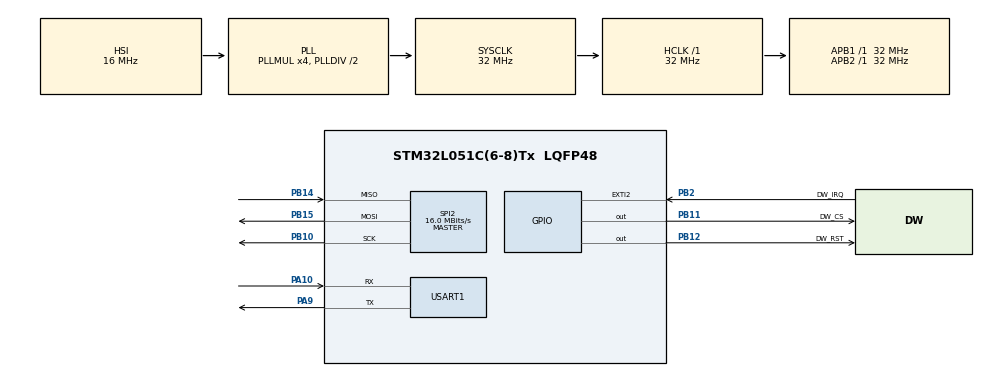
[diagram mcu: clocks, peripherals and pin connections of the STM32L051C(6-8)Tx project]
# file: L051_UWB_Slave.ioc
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Mcu.Family=STM32L0
Mcu.Name=STM32L051C(6-8)Tx
Mcu.Package=LQFP48
NVIC.EXTI2_3_IRQn=true\:0\:0\:false\:false\:true\:true\:true
PA10.Mode=Asynchronous
PA10.Signal=USART1_RX
PA9.Mode=Asynchronous
PA9.Signal=USART1_TX
PB10.Mode=Full_Duplex_Master
PB10.Signal=SPI2_SCK
PB11.GPIO_Label=DW_CS
PB11.GPIO_Speed=GPIO_SPEED_FREQ_VERY_HIGH
PB11.PinState=GPIO_PIN_SET
PB11.Signal=GPIO_Output
PB12.GPIO_Label=DW_RST
PB12.GPIO_Speed=GPIO_SPEED_FREQ_VERY_HIGH
PB12.PinState=GPIO_PIN_SET
PB12.Signal=GPIO_Output
PB14.Mode=Full_Duplex_Master
PB14.Signal=SPI2_MISO
PB15.Mode=Full_Duplex_Master
PB15.Signal=SPI2_MOSI
PB2.GPIO_Label=DW_IRQ
PB2.Signal=GPXTI2
PH0-OSC_IN.Mode=HSE-External-Oscillator
PH0-OSC_IN.Signal=RCC_OSC_IN
PH1-OSC_OUT.Mode=HSE-External-Oscillator
PH1-OSC_OUT.Signal=RCC_OSC_OUT
ProjectManager.HeapSize=0x200
ProjectManager.StackSize=0x400
ProjectManager.TargetToolchain=EWARM V8.32
RCC.AHBFreq_Value=32000000
RCC.APB1Freq_Value=32000000
RCC.APB1TimFreq_Value=32000000
RCC.APB2Freq_Value=32000000
RCC.APB2TimFreq_Value=32000000
RCC.HCLKFreq_Value=32000000
RCC.HSE_VALUE=8000000
RCC.HSI16_VALUE=16000000
RCC.HSI_VALUE=16000000
RCC.LSE_VALUE=32768
RCC.MSI_VALUE=2097000
RCC.PLLMUL=RCC_PLLMUL_4
RCC.SYSCLKFreq_VALUE=32000000
RCC.SYSCLKSource=RCC_SYSCLKSOURCE_PLLCLK
RCC.VCOOutputFreq_Value=64000000
SPI2.CalculateBaudRate=16.0 MBits/s
SPI2.Direction=SPI_DIRECTION_2LINES
SPI2.Mode=SPI_MODE_MASTER
SPI2.VirtualType=VM_MASTER
USART1.VirtualMode-Asynchronous=VM_ASYNC
board=custom

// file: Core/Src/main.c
/* USER CODE BEGIN Header */
/**
  ******************************************************************************
  * @file           : main.c
  * @brief          : Main program body
  ******************************************************************************
  * @attention
  *
  * <h2><center>&copy; Copyright (c) 2021 STMicroelectronics.
  * All rights reserved.</center></h2>
  *
  * This software component is licensed by ST under BSD 3-Clause license,
  * the "License"; You may not use this file except in compliance with the
  * License. You may obtain a copy of the License at:
  *                        opensource.org/licenses/BSD-3-Clause
  *
  ******************************************************************************
  */
/* USER CODE END Header */
#include "main.h"
#include "spi.h"
#include "usart.h"
#include "gpio.h"

/* USER CODE BEGIN Includes */
#include "port.h"

// DW1000
#include "deca_device_api.h"
#include "deca_regs.h"

/* USER CODE END Includes */

void SystemClock_Config(void);

int main(void)
{

  /* MCU Configuration--------------------------------------------------------*/

  /* Reset of all peripherals, Initializes the Flash interface and the Systick. */
  HAL_Init();

  /* Configure the system clock */
  SystemClock_Config();

  /* Initialize all configured peripherals */
  MX_GPIO_Init();
  MX_SPI2_Init();
  MX_USART1_UART_Init();
  /* USER CODE BEGIN 2 */
  setup_DW1000RSTnIRQ(0);

  /* USER CODE END 2 */

  /* Infinite loop */
  while (1)
  {

  }
}

void SystemClock_Config(void)
{
  RCC_OscInitTypeDef RCC_OscInitStruct = {0};
  RCC_ClkInitTypeDef RCC_ClkInitStruct = {0};
  RCC_PeriphCLKInitTypeDef PeriphClkInit = {0};

  /** Configure the main internal regulator output voltage
  */
  __HAL_PWR_VOLTAGESCALING_CONFIG(PWR_REGULATOR_VOLTAGE_SCALE1);
  /** Initializes the RCC Oscillators according to the specified parameters
  * in the RCC_OscInitTypeDef structure.
  */
  RCC_OscInitStruct.OscillatorType = RCC_OSCILLATORTYPE_HSI;
  RCC_OscInitStruct.HSIState = RCC_HSI_ON;
  RCC_OscInitStruct.HSICalibrationValue = RCC_HSICALIBRATION_DEFAULT;
  RCC_OscInitStruct.PLL.PLLState = RCC_PLL_ON;
  RCC_OscInitStruct.PLL.PLLSource = RCC_PLLSOURCE_HSI;
  RCC_OscInitStruct.PLL.PLLMUL = RCC_PLLMUL_4;
  RCC_OscInitStruct.PLL.PLLDIV = RCC_PLLDIV_2;
  if (HAL_RCC_OscConfig(&RCC_OscInitStruct) != HAL_OK)
  {
    Error_Handler();
  }
  /** Initializes the CPU, AHB and APB buses clocks
  */
  RCC_ClkInitStruct.ClockType = RCC_CLOCKTYPE_HCLK|RCC_CLOCKTYPE_SYSCLK
                              |RCC_CLOCKTYPE_PCLK1|RCC_CLOCKTYPE_PCLK2;
  RCC_ClkInitStruct.SYSCLKSource = RCC_SYSCLKSOURCE_PLLCLK;
  RCC_ClkInitStruct.AHBCLKDivider = RCC_SYSCLK_DIV1;
  RCC_ClkInitStruct.APB1CLKDivider = RCC_HCLK_DIV1;
  RCC_ClkInitStruct.APB2CLKDivider = RCC_HCLK_DIV1;

  if (HAL_RCC_ClockConfig(&RCC_ClkInitStruct, FLASH_LATENCY_1) != HAL_OK)
  {
    Error_Handler();
  }
  PeriphClkInit.PeriphClockSelection = RCC_PERIPHCLK_USART1;
  PeriphClkInit.Usart1ClockSelection = RCC_USART1CLKSOURCE_PCLK2;
  if (HAL_RCCEx_PeriphCLKConfig(&PeriphClkInit) != HAL_OK)
  {
    Error_Handler();
  }
}

void Error_Handler(void)
{
  __disable_irq();
  while (1)
  {
  }
}

/************************ (C) COPYRIGHT STMicroelectronics *****END OF FILE****/
